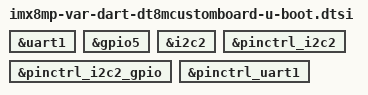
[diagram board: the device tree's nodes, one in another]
// SPDX-License-Identifier: GPL-2.0+
/*
 * Copyright 2019 NXP
 * Copyright 2020-2025 Variscite Ltd.
 */

#include "imx8mp-var-common-u-boot.dtsi"

&uart1 {
	bootph-pre-ram;
};

&gpio5 {
	bootph-all;
};

&i2c2 {
	bootph-all;
};

&pinctrl_i2c2 {
	bootph-all;
};

&pinctrl_i2c2_gpio {
	bootph-all;
};

&pinctrl_uart1 {
	bootph-pre-ram;
};
